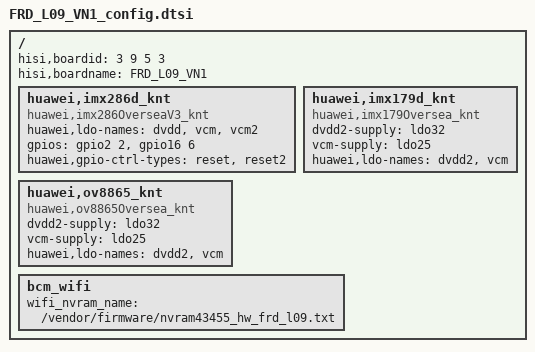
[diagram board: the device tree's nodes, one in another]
/**
 * Copyright (C) 2014 Hisilicon Ltd.
 *
 *  This program is free software; you can redistribute it and/or modify
 *  it under the terms of the GNU General Public License version 2 as
 *  publishhed by the Free Software Foundation.
 */

/include/ "FRD_L09_V4_config.dtsi"
/ {
	hisi,boardid = <3 9 5 3>;
	hisi,boardname = "FRD_L09_VN1";

	huawei,imx286d_knt{
		compatible = "huawei,imx286OverseaV3_knt";
		huawei,ldo-names = "dvdd", "vcm", "vcm2";
		gpios = <&gpio2 2 0 &gpio16 6 0>;
		huawei,gpio-ctrl-types = "reset", "reset2";
	};
	huawei,imx179d_knt{
		compatible = "huawei,imx179Oversea_knt";
		dvdd2-supply = <&ldo32>;
		vcm-supply = <&ldo25>;
		huawei,ldo-names = "dvdd2", "vcm";
	};
	huawei,ov8865_knt{
		compatible = "huawei,ov8865Oversea_knt";
		dvdd2-supply = <&ldo32>;
		vcm-supply = <&ldo25>;
		huawei,ldo-names = "dvdd2", "vcm";
	};
	bcm_wifi{
		wifi_nvram_name = "/vendor/firmware/nvram43455_hw_frd_l09.txt";
	};
};
